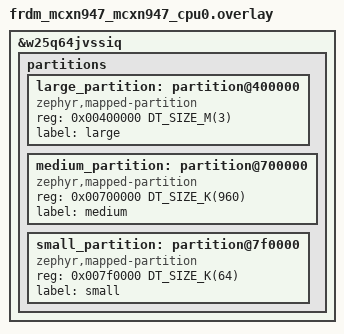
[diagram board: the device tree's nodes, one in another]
/*
 * Copyright 2025 NXP
 *
 * SPDX-License-Identifier: Apache-2.0
 */

/delete-node/ &storage_partition;

&w25q64jvssiq {
	partitions {
		large_partition: partition@400000 {
			compatible = "zephyr,mapped-partition";
			reg = <0x00400000 DT_SIZE_M(3)>;
			label = "large";
		};

		medium_partition: partition@700000 {
			compatible = "zephyr,mapped-partition";
			reg = <0x00700000 DT_SIZE_K(960)>;
			label = "medium";
		};

		small_partition: partition@7f0000 {
			compatible = "zephyr,mapped-partition";
			reg = <0x007f0000 DT_SIZE_K(64)>;
			label = "small";
		};
	};
};
